# psoc4100s register map
Vendor: Infineon Technologies; Series: PSOC4100S; File version: 1.0
CPU: CM0PLUS r0p1, little endian, MPU, no FPU, VTOR, 2 interrupt priority bits, 20 interrupts
Registers are 32-bit, read-write, reset 0x0 unless marked. A register's access mark holds for its fields unless they carry their own. Offsets are from the block's base; [hi:lo] are bit positions; lines under a group give offsets from that group; {n}, {i} and the like mark numbered series.

## SPCIF — Flash Control Interface
Base 0x40110000
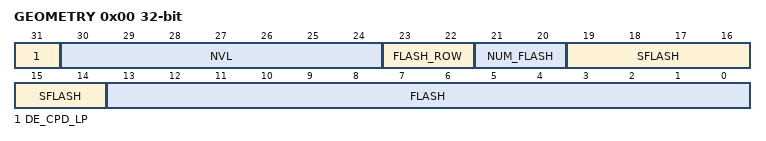
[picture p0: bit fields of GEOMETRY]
0x00 GEOMETRY (reset mask 0x80000000) — Flash/NVL geometry information
  [31] DE_CPD_LP — 0': SRAM busy wait loop has not been copied. '1': Busy wait loop has been written into SRAM.
  [30:24] NVL ro — NVLatch size in Byte multiples (chip dependent): '0': 0 Bytes '1': 1 Byte ... '127': 127 Bytes
  [23:22] FLASH_ROW ro — Page size in 64 Byte multiples (chip dependent): '0': 64 byte '1': 128 byte '2': 192 byte '3': 256 byte The page size is used to determine the number of Bytes in a page for Flash page based operations (e.g. PGM_PAGE). Note: the field name FLASH_ROW is misleading, as this field specifies the number of Bytes in a page, rather than the number of Bytes in a row. In a single plane flash macro architecture, a page consists of a single row. However, in a multi plane flash macro architecture, a page consists of multiple rows from different planes.
  [21:20] NUM_FLASH ro — Number of flash macros (chip dependent): '0': 1 flash macro '1': 2 flash macros '2': 3 flash macros '3': 4 flash macros
  [19:14] SFLASH ro — Supervisory flash capacity in 256 Byte multiples (chip dependent). If multiple flash macros are present, this field provides the supervisory flash capacity of all flash macros together: '0': 256 Bytes. '1': 2*256 Bytes. ... '63': 64*256 Bytes.
  [13:0] FLASH ro — Regular flash capacity in 256 Byte multiples (chip dependent). If multiple flash macros are present, this field provides the flash capacity of all flash macros together: '0': 256 Bytes. '1': 2*256 Bytes. ... '16383': 16384*256 Bytes.
0x1C NVL_WR_DATA — NVL write data register
  [7:0] DATA — Data to be written to NVLatch array
0x7F0 INTR — SPCIF interrupt request register
  [0] TIMER write-1-clears — Timer counter value reaches '0'. Set to '1', when event is detected. Write INTR field with '1', to clear bit. Write INTR_SET field with '1', to set bit.
0x7F4 INTR_SET — SPCIF interrupt set request register
  [0] TIMER write-1-sets — Write INTR_SET field with '1' to set corresponding INTR field.
0x7F8 INTR_MASK — SPCIF interrupt mask register
  [0] TIMER — Mask for corresponding field in INTR register.
0x7FC INTR_MASKED ro — SPCIF interrupt masked request register
  [0] TIMER — Logical and of corresponding request and mask fields.

## PASS0 — PASS top-level MMIO (DSABv2, INTR)
Base 0x403F0000
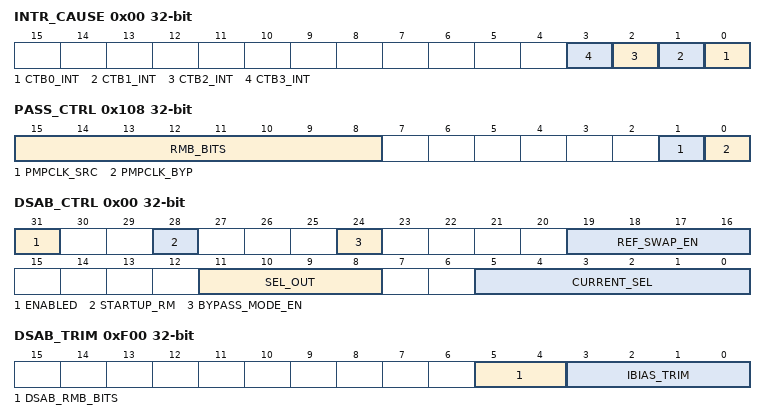
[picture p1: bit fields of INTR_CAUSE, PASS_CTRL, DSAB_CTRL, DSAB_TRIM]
0x00 INTR_CAUSE ro — Interrupt cause register
  [n] CTB{n}_INT (n=0..3) — CTB{n} interrupt pending
0x30 DFT_CTRL — DFT control register
  [0] DSAB_ADFT_RES_EN — Close the switch to connect the DSAB ADFT resistor to the AMUXBUS
0x108 PASS_CTRL — PASS Control
  [15:8] RMB_BITS — Risk mitigation bits
  [1] PMPCLK_SRC — - 0: Pump clk is clk_hf - 1: Pump clk is direct from SRSS
  [0] PMPCLK_BYP — - 0: Pump clk is clk_hf/2 - 1: Pump clk is selected from PMPCLK_SRC
0xE00 DSAB group — DSAB configuration
  0x00 DSAB_CTRL — global DSAB control
    [31] ENABLED — This field (along with SEL_OUT and REF_SWAP_EN) provides bitwise selection of the current sources that drive the DSAB ZTC and PTAT outputs. See SEL_OUT field for truth tables. In SRSSLT devices, in active mode, this bit is overridden to '1', that is - it is always enabled in active mode.
    [28] STARTUP_RM — Risk mitigation control 1 - Force start the startup circuit
    [24] BYPASS_MODE_EN — 0 - DSAB PTAT generator is powered from DSAB regulator: VDDA must be at least 2.4V 1 - DSAB PTAT generator is pwoered directly from VDDA: VDDA cannot exceed 4.0V
    [19:16] REF_SWAP_EN — This field (along with SEL_OUT and ENABLED) provides bitwise selection of the current sources that drive the DSAB ZTC and PTAT outputs. See SEL_OUT field for truth tables.
    [11:8] SEL_OUT
    [5:0] CURRENT_SEL — DSAB DAC control field Nominal DSAB Output Current = CURRENT_SEL * 0.075 uA In products with SRSS-LITE, this setting impacts the CTB(m) offset. A value of 0x20 is used during factory trim and is required to maintain low offsets across temperature variation. If a different setting is used then a periodic re-trim of CTB(m) offset should be performed.
  0x04 DSAB_DFT — DFT bits
    [3:0] EN_DFT — - 0: DSAB DFT disabled - 1: DSAB DFT enabled (connect output to amuxbus) 0001 - PTAT<0> 0010 - PTAT<1> 0011 - PTAT<1:0> 0100 - PTAT<2> 0111 - PTAT<2:0> 1000 - PTAT<3> 1111 - PTAT<3:0> 1001 - DSAB Reg Out
0xF00 DSAB_TRIM — DSAB Trim bits
  [5:4] DSAB_RMB_BITS — Risk mitigation bits
  [3:0] IBIAS_TRIM — 1111=lowest, 0000=highest

## Notices in the file
(c) 2016-2026, Infineon Technologies AG or an affiliate of
Infineon Technologies AG.
SPDX-License-Identifier: Apache-2.0
Licensed under the Apache License, Version 2.0 (the "License");
you may not use this file except in compliance with the License.
You may obtain a copy of the License at
http://www.apache.org/licenses/LICENSE-2.0
Unless required by applicable law or agreed to in writing, software
distributed under the License is distributed on an "AS IS" BASIS,
WITHOUT WARRANTIES OR CONDITIONS OF ANY KIND, either express or implied.
See the License for the specific language governing permissions and
limitations under the License.
